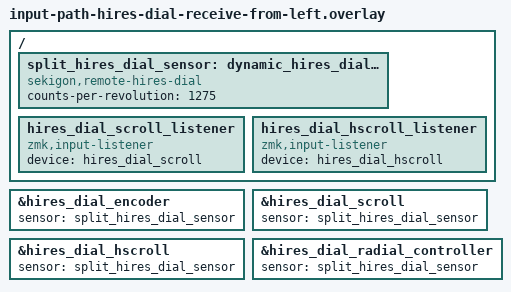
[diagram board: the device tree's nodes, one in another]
/ {
    /* Split HIRES events use sensor index 2; this device never emits local events. */
    split_hires_dial_sensor: dynamic_hires_dial_sensor: split_hires_dial_sensor {
        compatible = "sekigon,remote-hires-dial";
        counts-per-revolution = <1275>;
    };

    hires_dial_scroll_listener {
        compatible = "zmk,input-listener";
        device = <&hires_dial_scroll>;
    };

    hires_dial_hscroll_listener {
        compatible = "zmk,input-listener";
        device = <&hires_dial_hscroll>;
    };
};

&hires_dial_encoder {
    sensor = <&split_hires_dial_sensor>;
};

&hires_dial_scroll {
    sensor = <&split_hires_dial_sensor>;
};

&hires_dial_hscroll {
    sensor = <&split_hires_dial_sensor>;
};

&hires_dial_radial_controller {
    sensor = <&split_hires_dial_sensor>;
};
